AUTOSAR XML (schema 4-3-0)
package /App_DTC
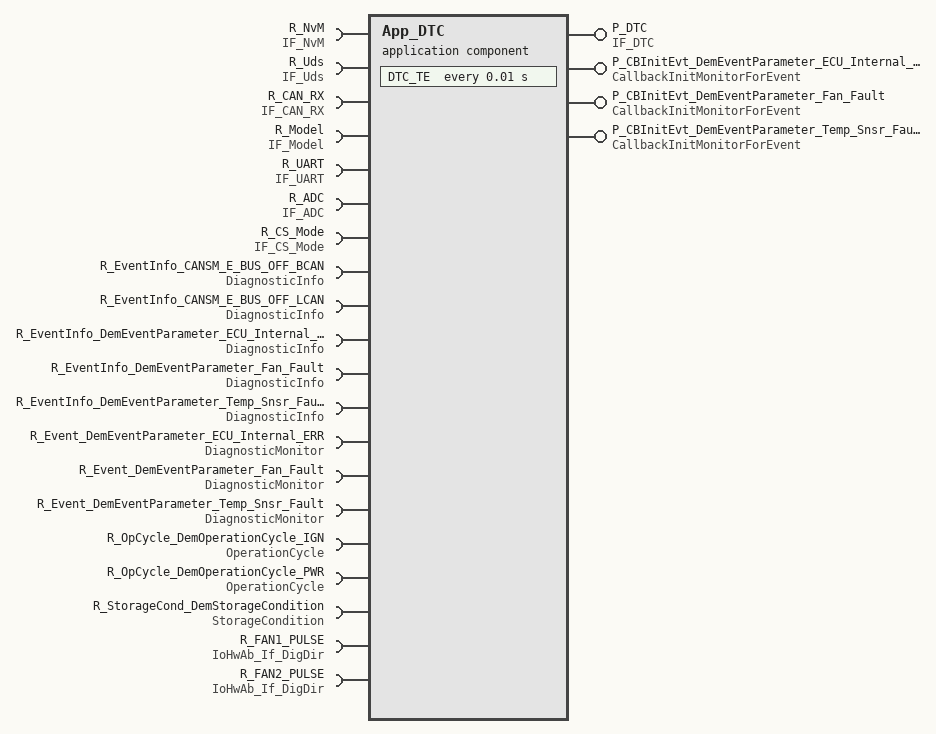
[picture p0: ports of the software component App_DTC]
  application sw component type App_DTC
    provide port P_DTC: nonqueued-sender-com-spec=DTC_STR, provided-interface=IF_DTC
    7 x require port:
      R_NvM: nonqueued-receiver-com-spec=NvM_STR, required-interface=IF_NvM
      R_Uds: nonqueued-receiver-com-spec=Uds_STR, required-interface=IF_Uds
      R_CAN_RX: nonqueued-receiver-com-spec=CAN_RX_STR, required-interface=IF_CAN_RX
      R_Model: nonqueued-receiver-com-spec=Model_STR, required-interface=IF_Model
      R_UART: nonqueued-receiver-com-spec=UART_STR, required-interface=IF_UART
      R_ADC: nonqueued-receiver-com-spec=ADC_STR, required-interface=IF_ADC
      R_CS_Mode: required-com-specs=[ModeInit, NvMInit, ApplicationInit], required-interface=IF_CS_Mode
    provide port P_CBInitEvt_DemEventParameter_ECU_Internal_ERR: server-com-spec{operation=InitMonitorForEvent, queue-length=1}, provided-interface=CallbackInitMonitorForEvent
    provide port P_CBInitEvt_DemEventParameter_Fan_Fault: server-com-spec{operation=InitMonitorForEvent, queue-length=1}, provided-interface=CallbackInitMonitorForEvent
    provide port P_CBInitEvt_DemEventParameter_Temp_Snsr_Fault: server-com-spec{operation=InitMonitorForEvent, queue-length=1}, provided-interface=CallbackInitMonitorForEvent
    13 x require port:
      R_EventInfo_CANSM_E_BUS_OFF_BCAN: client-com-spec=GetEventStatus, required-interface=DiagnosticInfo
      R_EventInfo_CANSM_E_BUS_OFF_LCAN: client-com-spec=GetEventStatus, required-interface=DiagnosticInfo
      R_EventInfo_DemEventParameter_ECU_Internal_ERR: client-com-spec=GetEventStatus, required-interface=DiagnosticInfo
      R_EventInfo_DemEventParameter_Fan_Fault: client-com-spec=GetEventStatus, required-interface=DiagnosticInfo
      R_EventInfo_DemEventParameter_Temp_Snsr_Fault: client-com-spec=GetEventStatus, required-interface=DiagnosticInfo
      R_Event_DemEventParameter_ECU_Internal_ERR: client-com-spec=SetEventStatus, required-interface=DiagnosticMonitor
      R_Event_DemEventParameter_Fan_Fault: client-com-spec=SetEventStatus, required-interface=DiagnosticMonitor
      R_Event_DemEventParameter_Temp_Snsr_Fault: client-com-spec=SetEventStatus, required-interface=DiagnosticMonitor
      R_OpCycle_DemOperationCycle_IGN: client-com-spec=SetOperationCycleState, required-interface=OperationCycle
      R_OpCycle_DemOperationCycle_PWR: client-com-spec=SetOperationCycleState, required-interface=OperationCycle
      R_StorageCond_DemStorageCondition: client-com-spec=SetStorageCondition, required-interface=StorageCondition
      R_FAN1_PULSE: client-com-spec=ReadDirect, required-interface=IoHwAb_If_DigDir
      R_FAN2_PULSE: client-com-spec=ReadDirect, required-interface=IoHwAb_If_DigDir
    behavior InternalBehavior: data-type-mapping=DataTypeMappingSet_WPC
      timing event TE_DTC_TE: start-on-event=DTC_TE, period=0.01
      operation invoked event OIE_ECU_Internal_ERR_InitMonitorForEvent_IE_P_CBInitEvt_DemEventParameter_ECU_Internal_ERR_InitMonitorForEvent: start-on-event=ECU_Internal_ERR_InitMonitorForEvent_IE, operation=P_CBInitEvt_DemEventParameter_ECU_Internal_ERR.InitMonitorForEvent
      operation invoked event OIE_FanFault_InitMonitorForEvent_IE_P_CBInitEvt_DemEventParameter_Fan_Fault_InitMonitorForEvent: start-on-event=Fan_Fault_InitMonitorForEvent_IE, operation=P_CBInitEvt_DemEventParameter_Fan_Fault.InitMonitorForEvent
      operation invoked event OIE_TempSnsr_Fault_InitMonitorForEvent_IE_P_CBInitEvt_DemEventParameter_Temp_Snsr_Fault_InitMonitorForEvent: start-on-event=TempSnsr_Fault_InitMonitorForEvent_IE, operation=P_CBInitEvt_DemEventParameter_Temp_Snsr_Fault.InitMonitorForEvent
      4 x runnable:
        DTC_TE: symbol=DTC_TE_Runnable
          data-receive-point-by-arguments:
            6 x access, all with scope=COMMUNICATION-INTER-ECU:
              DRPBA_DTC_TE_R_UART_Structure: accessed-variable=R_UART.UART_STR
              DRPBA_DTC_TE_IF_ADC_ADC_STR: accessed-variable=R_ADC.ADC_STR
              DRPBA_DTC_TE_R_Model_Model_COMM_STR: accessed-variable=R_Model.Model_STR
              DRPBA_DTC_TE_R_CAN_RX_CAN_RX_STR: accessed-variable=R_CAN_RX.CAN_RX_STR
              DRPBA_DTC_TE_R_Uds_Uds_STR: accessed-variable=R_Uds.Uds_STR
              DRPBA_DTC_TE_R_NvM_NvM_STR: accessed-variable=R_NvM.NvM_STR
          data-send-points:
            access DSP_DTC_TE_P_DTC_DTC_STR: accessed-variable=P_DTC.DTC_STR, scope=COMMUNICATION-INTER-ECU
          16 x sync call:
            SSCP_DTC_TE_R_CS_Mode_ApplicationInit: operation=R_CS_Mode.ApplicationInit
            SSCP_DTC_TE_R_CS_Mode_ModeInit: operation=R_CS_Mode.ModeInit
            SSCP_DTC_TE_R_CS_Mode_NvMInit: operation=R_CS_Mode.NvMInit
            SSCP_DTC_TE_R_EventInfo_CANSM_E_BUS_OFF_BCAN_GetEventStatus: operation=R_EventInfo_CANSM_E_BUS_OFF_BCAN.GetEventStatus
            SSCP_DTC_TE_R_EventInfo_CANSM_E_BUS_OFF_LCAN_GetEventStatus: operation=R_EventInfo_CANSM_E_BUS_OFF_LCAN.GetEventStatus
            SSCP_DTC_TE_R_EventInfo_DemEventParameter_ECU_Internal_ERR_GetEventStatus: operation=R_EventInfo_DemEventParameter_ECU_Internal_ERR.GetEventStatus
            SSCP_DTC_TE_R_EventInfo_DemEventParameter_Fan_Fault_GetEventStatus: operation=R_EventInfo_DemEventParameter_Fan_Fault.GetEventStatus
            SSCP_DTC_TE_R_EventInfo_DemEventParameter_Temp_Snsr_Fault_GetEventStatus: operation=R_EventInfo_DemEventParameter_Temp_Snsr_Fault.GetEventStatus
            SSCP_DTC_TE_R_Event_DemEventParameter_ECU_Internal_ERR_SetEventStatus: operation=R_Event_DemEventParameter_ECU_Internal_ERR.SetEventStatus
            SSCP_DTC_TE_R_Event_DemEventParameter_Fan_Fault_SetEventStatus: operation=R_Event_DemEventParameter_Fan_Fault.SetEventStatus
            SSCP_DTC_TE_R_Event_DemEventParameter_Temp_Snsr_Fault_SetEventStatus: operation=R_Event_DemEventParameter_Temp_Snsr_Fault.SetEventStatus
            SSCP_DTC_TE_R_OpCycle_DemOperationCycle_IGN_SetOperationCycleState: operation=R_OpCycle_DemOperationCycle_IGN.SetOperationCycleState
            SSCP_DTC_TE_R_OpCycle_DemOperationCycle_PWR_SetOperationCycleState: operation=R_OpCycle_DemOperationCycle_PWR.SetOperationCycleState
            SSCP_DTC_TE_R_StorageCond_DemStorageCondition_SetStorageCondition: operation=R_StorageCond_DemStorageCondition.SetStorageCondition
            SSCP_DTC_TE_R_FAN1_PULSE_ReadDirect: operation=R_FAN1_PULSE.ReadDirect
            SSCP_DTC_TE_R_FAN2_PULSE_ReadDirect: operation=R_FAN2_PULSE.ReadDirect
        ECU_Internal_ERR_InitMonitorForEvent_IE: symbol=ECU_Internal_ERR_InitMonitorForEvent_IE_Runnable
        Fan_Fault_InitMonitorForEvent_IE: symbol=Fan_Fault_InitMonitorForEvent_IE_Runnable
        TempSnsr_Fault_InitMonitorForEvent_IE: symbol=TempSnsr_Fault_InitMonitorForEvent_IE_Runnable
  sender receiver interface IF_DTC  # NFC SWC Output
    data DTC_STR: type=IDT_DTC_STR
